VERSION ""

NS_ :

BS_:

BU_: BCM_ECU Mirror_ECU

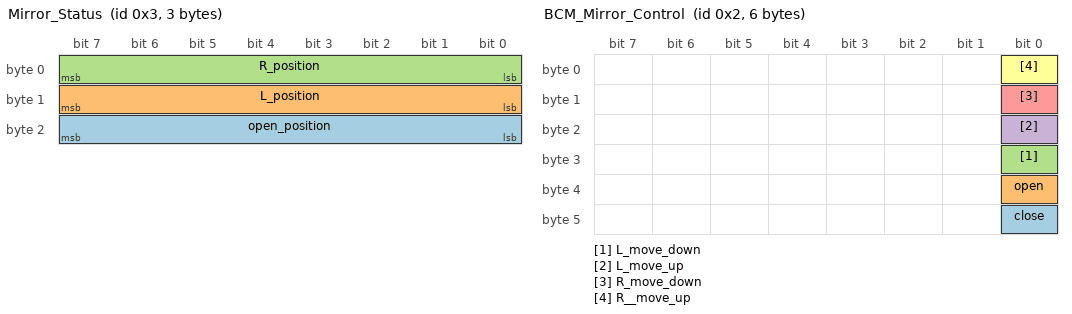
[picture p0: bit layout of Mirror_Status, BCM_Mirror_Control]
BO_ 3 Mirror_Status: 3 Mirror_ECU
 SG_ open_position : 16|8@1- (1,0) [0|90] ""  BCM_ECU
 SG_ L_position : 8|8@1+ (1,0) [0|180] ""  BCM_ECU
 SG_ R_position : 0|8@1+ (1,0) [0|180] ""  BCM_ECU

BO_ 2 BCM_Mirror_Control: 6 BCM_ECU
 SG_ close : 40|1@1+ (1,0) [0|0] ""  Mirror_ECU
 SG_ open : 32|1@1+ (1,0) [0|0] ""  Mirror_ECU
 SG_ L_move_down : 24|1@1+ (1,0) [0|0] ""  Mirror_ECU
 SG_ L_move_up : 16|1@1+ (1,0) [0|0] ""  Mirror_ECU
 SG_ R_move_down : 8|1@1+ (1,0) [0|0] ""  Mirror_ECU
 SG_ R__move_up : 0|1@1+ (1,0) [0|0] ""  Mirror_ECU

BO_ 1 Mirror_NM_Message: 2 Mirror_ECU
 SG_ Mirror_NM_Awake : 8|1@1+ (1,0) [0|0] ""  BCM_ECU
 SG_ Mirror_NM_Sleep : 0|1@1+ (1,0) [0|0] ""  BCM_ECU

BO_ 0 BCM_NM_Message: 2 BCM_ECU
 SG_ BCM_NM_Sleep : 8|1@1+ (1,0) [0|0] ""  Mirror_ECU
 SG_ BCM_NM_Wakeup : 0|1@1+ (1,0) [0|0] ""  Mirror_ECU

BA_DEF_ BO_  "CANFD_BRS" ENUM  "0","1";
BA_DEF_  "DBName" STRING ;
BA_DEF_  "BusType" STRING ;
BA_DEF_ BO_  "VFrameFormat" ENUM  "StandardCAN","ExtendedCAN","reserved","reserved","reserved","reserved","reserved","reserved","reserved","reserved","reserved","reserved","reserved","reserved","StandardCAN_FD","ExtendedCAN_FD";
BA_DEF_DEF_  "CANFD_BRS" "1";
BA_DEF_DEF_  "DBName" "";
BA_DEF_DEF_  "BusType" "";
BA_DEF_DEF_  "VFrameFormat" "StandardCAN";
BA_ "BusType" "CAN FD";
BA_ "DBName" "MirrorControlSystem";
